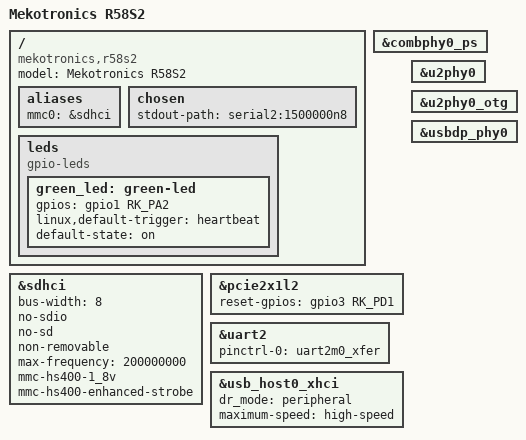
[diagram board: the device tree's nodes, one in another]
// SPDX-License-Identifier: (GPL-2.0+ OR MIT)
/*
 * Mekotronics R58S2 - u-boot device tree
 *
 * Minimal DTS for u-boot: eMMC, LED, USB gadget.
 * The full board DTS lives in the kernel tree.
 */

/dts-v1/;
#include "rk3588s.dtsi"
#include "rk3588s-u-boot.dtsi"
#include <dt-bindings/gpio/gpio.h>
#include <dt-bindings/input/input.h>

/ {
	model = "Mekotronics R58S2";
	compatible = "mekotronics,r58s2", "rockchip,rk3588s";

	aliases {
		mmc0 = &sdhci;
	};

	chosen {
		stdout-path = "serial2:1500000n8";
	};

	leds: leds {
		compatible = "gpio-leds";
		green_led: green-led {
			gpios = <&gpio1 RK_PA2 GPIO_ACTIVE_HIGH>;
			linux,default-trigger = "heartbeat";
			default-state = "on";
			status = "okay";
		};
	};
};

&sdhci {
	bus-width = <8>;
	no-sdio;
	no-sd;
	non-removable;
	max-frequency = <200000000>;
	mmc-hs400-1_8v;
	mmc-hs400-enhanced-strobe;
	status = "okay";
};

&combphy0_ps {
	status = "okay";
};

&pcie2x1l2 {
	reset-gpios = <&gpio3 RK_PD1 GPIO_ACTIVE_HIGH>;
	status = "okay";
};

&u2phy0 {
	status = "okay";
};

&u2phy0_otg {
	status = "okay";
};

&usbdp_phy0 {
	status = "okay";
};

&uart2 {
	pinctrl-0 = <&uart2m0_xfer>;
	status = "okay";
};

&usb_host0_xhci {
	dr_mode = "peripheral";
	maximum-speed = "high-speed";
	status = "okay";
};
